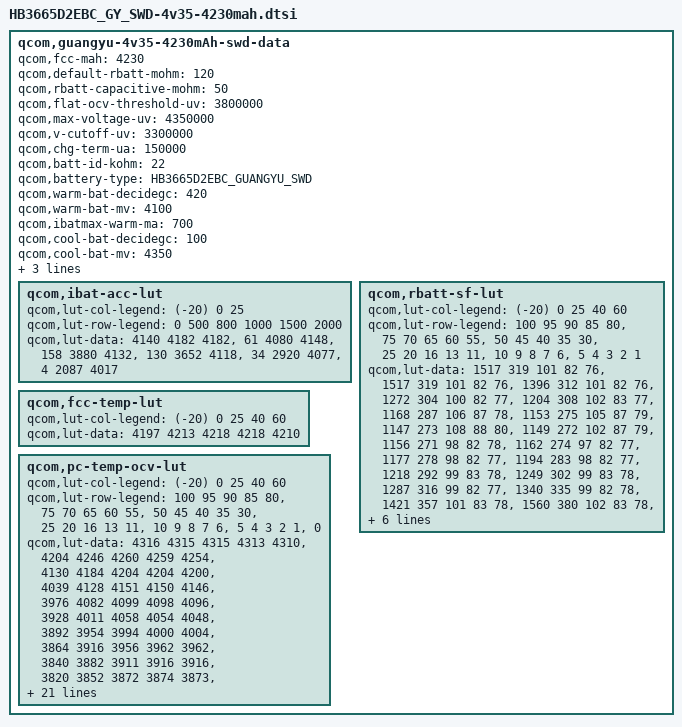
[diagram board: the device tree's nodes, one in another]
/* Copyright (c) 2013, The Linux Foundation. All rights reserved.
 *
 * This program is free software; you can redistribute it and/or modify
 * it under the terms of the GNU General Public License version 2 and
 * only version 2 as published by the Free Software Foundation.
 *
 * This program is distributed in the hope that it will be useful,
 * but WITHOUT ANY WARRANTY; without even the implied warranty of
 * MERCHANTABILITY or FITNESS FOR A PARTICULAR PURPOSE.  See the
 * GNU General Public License for more details.
 */
qcom,guangyu-4v35-4230mAh-swd-data {
	qcom,fcc-mah = <4230>;
	qcom,default-rbatt-mohm = <120>;
	qcom,rbatt-capacitive-mohm = <50>;
	qcom,flat-ocv-threshold-uv = <3800000>;
	qcom,max-voltage-uv = <4350000>;
	/* <DTS2014101405060 caiwei 20141014 begin */
	qcom,v-cutoff-uv = <3300000>;
	/* DTS2014101405060 caiwei 20141014 end> */
	qcom,chg-term-ua = <150000>;
	qcom,batt-id-kohm = <22>;
	qcom,battery-type = "HB3665D2EBC_GUANGYU_SWD";

	/* < DTS2013120201997 liyuping 20131204 begin */
	qcom,warm-bat-decidegc = <420>;
	qcom,warm-bat-mv = <4100>;
	qcom,ibatmax-warm-ma = <700>;

	qcom,cool-bat-decidegc = <100>;
	qcom,cool-bat-mv = <4350>;
	qcom,ibatmax-cool-ma = <1280>;

	qcom,hot-bat-decidegc = <520>;
	qcom,cold-bat-decidegc = <0>;
	/* DTS2013120201997 liyuping 20131204 end >*/
	/* <DTS2014101405060 caiwei 20141014 begin */
	qcom,ibat-acc-lut {
	    qcom,lut-col-legend = <(-20) 0 25>;
		qcom,lut-row-legend = <0 500 800 1000 1500 2000>;
		qcom,lut-data = <4140 4182 4182>,
		                <61 4080 4148>,
						<158 3880 4132>,
						<130 3652 4118>,
						<34 2920 4077>,
						<4 2087 4017>;
	};
    /* DTS2014101405060 caiwei 20141014 end> */
	qcom,rbatt-sf-lut {
		qcom,lut-col-legend = <(-20) 0 25 40 60>;
		qcom,lut-row-legend = 
		    <100 95 90 85 80>,
				<75 70 65 60 55>,
				<50 45 40 35 30>,
				<25 20 16 13 11>,
				<10 9 8 7 6>,
				<5 4 3 2 1>;
		qcom,lut-data = 
				<1517 319 101 82 76>,
				<1517 319 101 82 76>,
				<1396 312 101 82 76>,
				<1272 304 100 82 77>,
				<1204 308 102 83 77>,
				<1168 287 106 87 78>,
				<1153 275 105 87 79>,
				<1147 273 108 88 80>,
				<1149 272 102 87 79>,
				<1156 271 98 82 78>,
				<1162 274 97 82 77>,
				<1177 278 98 82 77>,
				<1194 283 98 82 77>,
				<1218 292 99 83 78>,
				<1249 302 99 83 78>,
				<1287 316 99 82 77>,
				<1340 335 99 82 78>,
				<1421 357 101 83 78>,
				<1560 380 102 83 78>,
				<1714 403 102 84 78>,
				<1797 417 102 84 78>,
				<1902 432 104 85 80>,
				<2023 446 105 86 81>,
				<2107 453 107 88 82>,
				<2232 467 108 88 82>,
				<2478 484 108 86 80>,
				<2847 508 108 85 79>,
				<3400 540 111 87 80>,
				<4392 586 115 88 81>,
				<7376 673 126 93 88>;
	};

	qcom,fcc-temp-lut {
		qcom,lut-col-legend = <(-20) 0 25 40 60>;
		qcom,lut-data = <4197 4213 4218 4218 4210>;
	};

	qcom,pc-temp-ocv-lut {
		qcom,lut-col-legend = <(-20) 0 25 40 60>;
		qcom,lut-row-legend =
                <100 95 90 85 80>,
				<75 70 65 60 55>,
				<50 45 40 35 30>,
				<25 20 16 13 11>,
				<10 9 8 7 6>,
				<5 4 3 2 1>,
				<0>;
		qcom,lut-data =
				<4316 4315 4315 4313 4310>,
				<4204 4246 4260 4259 4254>,
				<4130 4184 4204 4204 4200>,
				<4039 4128 4151 4150 4146>,
				<3976 4082 4099 4098 4096>,
				<3928 4011 4058 4054 4048>,
				<3892 3954 3994 4000 4004>,
				<3864 3916 3956 3962 3962>,
				<3840 3882 3911 3916 3916>,
				<3820 3852 3872 3874 3873>,
				<3802 3826 3842 3844 3842>,
				<3786 3805 3820 3820 3819>,
				<3770 3790 3800 3801 3800>,
				<3755 3777 3784 3784 3782>,
				<3738 3764 3769 3766 3760>,
				<3718 3750 3754 3746 3734>,
				<3693 3730 3734 3726 3712>,
				<3668 3712 3714 3706 3693>,
				<3642 3698 3696 3688 3674>,
				<3618 3688 3690 3682 3670>,
				<3607 3682 3686 3680 3668>,
				<3592 3676 3684 3678 3666>,
				<3576 3668 3681 3675 3664>,
				<3558 3658 3677 3671 3659>,
				<3536 3642 3668 3662 3646>,
				<3507 3617 3643 3634 3614>,
				<3470 3580 3600 3588 3567>,
				<3422 3528 3540 3528 3506>,
				<3356 3454 3458 3444 3420>,
				<3248 3334 3326 3307 3274>,
				<3000 3000 3000 3000 3000>;
	};
};
